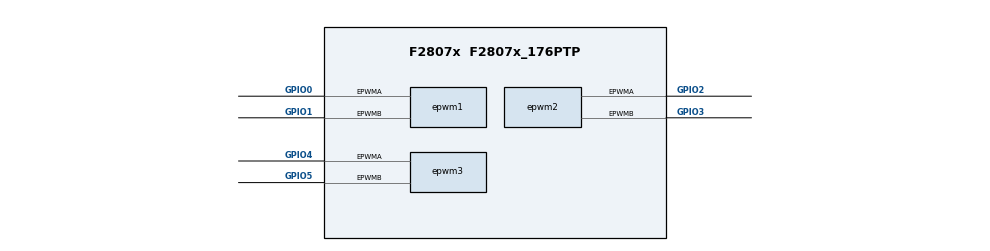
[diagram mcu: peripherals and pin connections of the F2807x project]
/**
 * @cliArgs --device "F2807x" --part "F2807x_176PTP" --package "F2807x_176PTP" --context "system"
 */


/**
 * Import the modules used in this configuration.
 */
const epwm  = scripting.addModule("/driverlib/epwm.js", {}, false);
const epwm1 = epwm.addInstance();
const epwm2 = epwm.addInstance();
const epwm3 = epwm.addInstance();

/**
 * Write custom configuration values to the imported modules.
 */

epwm1.$name                 = "myEPWM1";
epwm1.epwm.$assign          = "EPWM1";
epwm1.epwm.epwmaPin.$assign = "GPIO0";
epwm1.epwm.epwmbPin.$assign = "GPIO1";

epwm2.$name                 = "myEPWM2";
epwm2.epwm.$assign          = "EPWM2";
epwm2.epwm.epwmaPin.$assign = "GPIO2";
epwm2.epwm.epwmbPin.$assign = "GPIO3";

epwm3.$name                 = "myEPWM3";
epwm3.epwm.$assign          = "EPWM3";
epwm3.epwm.epwmaPin.$assign = "GPIO4";
epwm3.epwm.epwmbPin.$assign = "GPIO5";
